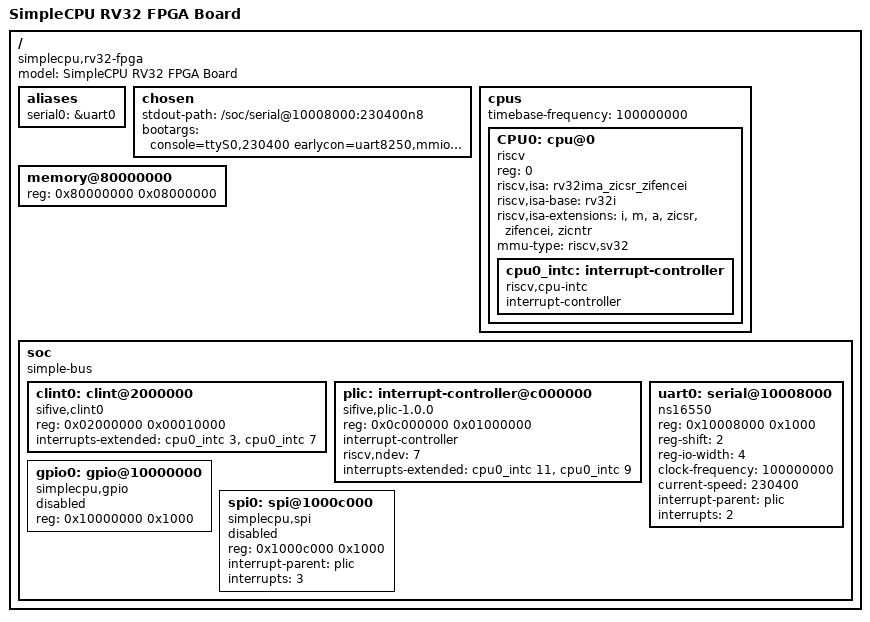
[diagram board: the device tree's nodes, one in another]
/dts-v1/;

/ {
    #address-cells = <1>;
    #size-cells = <1>;

    compatible = "simplecpu,rv32-fpga";
    model = "SimpleCPU RV32 FPGA Board";

    aliases {
        serial0 = &uart0;
    };

    chosen {
        stdout-path = "/soc/serial@10008000:230400n8";

        /*
         * 第一阶段建议先使用 initramfs。
         * 没有 initramfs 时，kernel 能打印日志后 panic 也算阶段性成功。
         */

        bootargs = "console=ttyS0,230400 earlycon=uart8250,mmio32,0x10008000,230400n8,100000000 rdinit=/init";

    };

    cpus {
        #address-cells = <1>;
        #size-cells = <0>;

        /*
         * 100 MHz = 0x05F5E100
         * 必须和 mtime / time CSR 的实际频率一致。
         */
        timebase-frequency = <100000000>;

        CPU0: cpu@0 {
            device_type = "cpu";
            reg = <0>;
            status = "okay";

            compatible = "riscv";

            /*
             * 第一阶段建议不要声明 f。
             * 即使硬件 misa 里有 F，如果 FPU/fcsr/mstatus.FS 尚未完全验证，
             * Linux 侧先按 soft-float 跑，减少变量。
             */
            /*
             * Keep riscv,isa for firmware and older software, and provide the
             * non-deprecated split properties required when Linux is built
             * with CONFIG_RISCV_ISA_FALLBACK disabled.
             */
            riscv,isa = "rv32ima_zicsr_zifencei";
            riscv,isa-base = "rv32i";
            riscv,isa-extensions = "i", "m", "a",
                                   "zicsr", "zifencei", "zicntr";

            mmu-type = "riscv,sv32";

            cpu0_intc: interrupt-controller {
                #interrupt-cells = <1>;
                interrupt-controller;
                compatible = "riscv,cpu-intc";
            };
        };
    };

    memory@80000000 {
        device_type = "memory";
        reg = <0x80000000 0x08000000>; /* 128 MiB */
    };

    soc {
        #address-cells = <1>;
        #size-cells = <1>;
        compatible = "simple-bus";
        ranges;

        /*
         * 假设你们稍后把 CLINT RTL 改成标准 SiFive CLINT 布局：
         *
         *   0x0200_0000: msip
         *   0x0200_4000: mtimecmp
         *   0x0200_BFF8: mtime
         *
         * interrupts-extended:
         *   3 = Machine software interrupt
         *   7 = Machine timer interrupt
         */
        clint0: clint@2000000 {
            compatible = "sifive,clint0", "riscv,clint0";
            reg = <0x02000000 0x00010000>;
            interrupts-extended = <&cpu0_intc 3>, <&cpu0_intc 7>;
        };

        /*
         * PLIC base = 0x0C00_0000
         * RTL 有 8 个 source 槽位，其中 source 0 按 PLIC 规范保留，
         * 因而有效的设备中断 ID 是 1..7。
         *
         * 注意：
         * PLIC 有 2 个 interrupt context:
         *   context 0 → M-mode (MEIP, interrupt 11)
         *   context 1 → S-mode (SEIP, interrupt 9)
         * RTL 确认: plic_eip[0]→ext_meip_in, plic_eip[1]→ext_seip_in
         * (system_top.sv lines 405-408, 854-855, 1673)
         */
        plic: interrupt-controller@c000000 {
            compatible = "sifive,plic-1.0.0";
            reg = <0x0c000000 0x01000000>;

            #address-cells = <0>;
            #interrupt-cells = <1>;
            interrupt-controller;

            riscv,ndev = <7>;
            interrupts-extended = <&cpu0_intc 11>, <&cpu0_intc 9>;
        };

        /*
         * UART base = 0x1000_8000
         * PLIC source ID = 2. Keep FIFO size omitted until the full 8250 FIFO
         * path is validated in RTL.
         *
         * 你们的 uart_16550a 使用 PADDR[4:2] 选择 8 个标准寄存器，
         * 即寄存器间隔 4 字节，所以需要 reg-shift = <2>。
         */
        uart0: serial@10008000 {
            compatible = "ns16550";
            reg = <0x10008000 0x1000>;

            reg-shift = <2>;
            reg-io-width = <4>;

            clock-frequency = <100000000>;
            current-speed = <230400>;

            interrupt-parent = <&plic>;
            interrupts = <2>;

            status = "okay";
        };

        /*
         * 下面这些外设先不打开。
         * 第一阶段只需要 UART console。
         * GPIO / SPI 等后续等 kernel 能启动后再补。
         */

        gpio0: gpio@10000000 {
            compatible = "simplecpu,gpio";
            reg = <0x10000000 0x1000>;
            status = "disabled";
        };

        spi0: spi@1000c000 {
            compatible = "simplecpu,spi";
            reg = <0x1000c000 0x1000>;
            interrupt-parent = <&plic>;
            interrupts = <3>;
            status = "disabled";
        };
    };
};
